# ESP32-P4-LP register map
Vendor: ESPRESSIF SYSTEMS (SHANGHAI) CO., LTD.; Series: ESP32 P-Series; File version: 3
32-bit RISC-V LP coprocessor on ESP32-P4 (ECO5+ silicon only)
CPU: RV32IMAC r0p0, little endian, no MPU, no FPU, 0 interrupt priority bits
Address unit: 32 bits
Registers are 32-bit, read-write, reset 0x0 unless marked. A register's access mark holds for its fields unless they carry their own. Offsets are from the block's base; lines under a group give offsets from that group; [hi:lo] are bit positions; {n}, {i} and the like mark numbered series; 'fields as' and 'values as' point back to an identical list; <NAME> marks a mode.

## Memory map
0x500A5800 LP2HP_PERI_PMS size 0xC0
0x50110000 LP_SYS size 0x124 — LP_SYS Peripheral
0x50111000 LP_AON_CLKRST size 0x54 — LP_AON_CLKRST Peripheral
0x50112000 LP_TIMER size 0x4C — Low-power Timer
0x50113000 LP_ANA_PERI size 0x144 — LP_ANA_PERI Peripheral
0x50114000 LP_HUK size 0x1A8 — LP_HUK Peripheral
0x50115000 PMU size 0x10E0
0x50116000 LP_WDT size 0x38 — Low-power Watchdog Timer
0x50118000 LP_MAILBOX size 0x320
0x50120000 LP_PERI size 0x2C — LP_PERI Peripheral
0x50121000 LP_UART size 0x84 — Low-power UART (Universal Asynchronous Receiver-Transmitter) Controller
0x50122000 LP_I2C0 size 0x440
0x50123000 LP_SPI size 0x560
0x50124000 LP_I2C_ANA_MST size 0x3C — LP_I2C_ANA_MST Peripheral
0x50125000 LP_I2S0 size 0x98 — Low-power I2S (Inter-IC Sound) Controller 0
0x50126000 LP_TRNG size 0x80
0x50127000 LP_ADC size 0x80 — Low-power Analog to Digital Converter
0x50128000 LP_TOUCH size 0x64 — LP_TOUCH Peripheral
0x5012A000 LP_GPIO size 0xEC — Low-power General Purpose Input/Output
0x5012B000 LP_IO_MUX size 0x54 — Low-power Input/Output Multiplexer
0x5012C000 LP_INTR size 0x18 — Low-power Interrupt Controller
0x5012E000 LP_PERI_PMS size 0x2A0
0x5012E800 HP2LP_PERI_PMS size 0xE0
0x5012F000 LP_TSENS size 0x38 — Low-power Temperature Sensor
0x60093000 PAU size 0x44 — PAU Peripheral

## Interrupts
3 LP_SW (LP_INTR) — LP software interrupt
7 LP_UART — LP UART interrupt
11 LP_SPI — LP SPI interrupt
15 LP_TRNG — LP TRNG interrupt
16 LP_I2C (LP_I2C0) — LP I2C interrupt
17 LP_IO (LP_GPIO) — LP GPIO/IO MUX interrupt
18 LP_ADC — LP ADC interrupt
19 LP_TOUCH — LP Touch sensor interrupt
20 LP_TSENS — LP temperature sensor interrupt
21 LP_EFUSE (LP_HUK) — LP eFuse / HUK interrupt
22 LP_SYSREG (LP_SYS) — LP system register interrupt
23 LP_ANA_PERI — LP analog peripheral interrupt
24 LP_PMU (PMU) — LP PMU interrupt
25 LP_MAILBOX — LP mailbox interrupt
26 LP_TIMER — LP timer interrupt
27 LP_WDT — LP watchdog interrupt
28 LP_RTC (LP_TIMER) — LP RTC interrupt

## LP2HP_PERI_PMS
Base 0x500A5800
0x00 TEE_LP2HP_PMS_DATE
  [31:0] TEE_TEE_DATE
0x04 TEE_PMS_CLK_EN
  [0] TEE_REG_CLK_EN
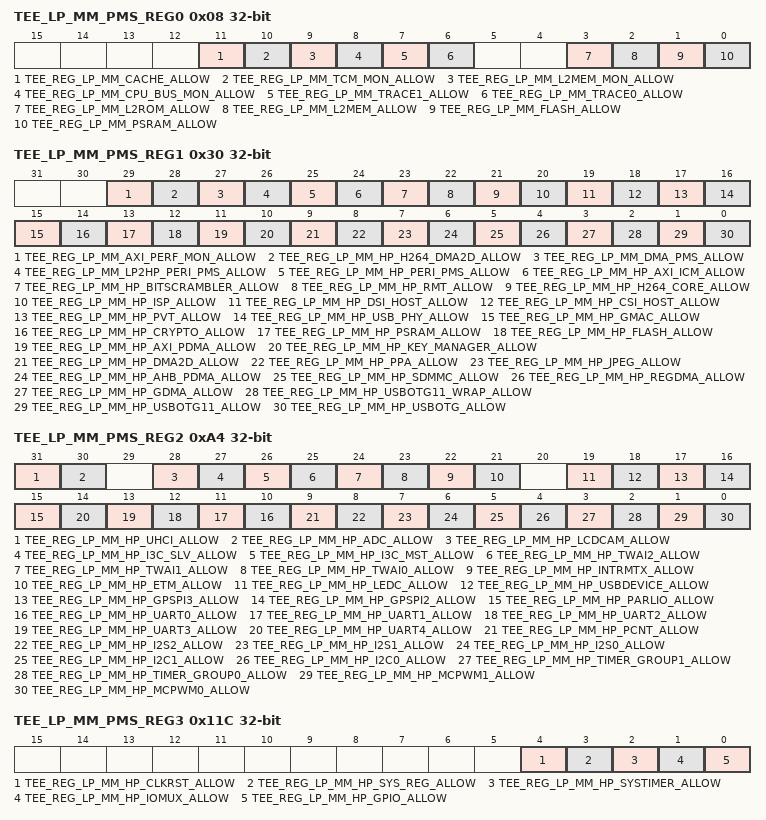
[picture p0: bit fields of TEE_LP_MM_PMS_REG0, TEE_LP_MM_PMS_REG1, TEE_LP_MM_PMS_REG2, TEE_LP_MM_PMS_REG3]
0x08 TEE_LP_MM_PMS_REG0
  [11] TEE_REG_LP_MM_CACHE_ALLOW, [10] TEE_REG_LP_MM_TCM_MON_ALLOW, [9] TEE_REG_LP_MM_L2MEM_MON_ALLOW, [8] TEE_REG_LP_MM_CPU_BUS_MON_ALLOW, [7] TEE_REG_LP_MM_TRACE1_ALLOW, [6] TEE_REG_LP_MM_TRACE0_ALLOW, [3] TEE_REG_LP_MM_L2ROM_ALLOW, [2] TEE_REG_LP_MM_L2MEM_ALLOW, [1] TEE_REG_LP_MM_FLASH_ALLOW, [0] TEE_REG_LP_MM_PSRAM_ALLOW
0x30 TEE_LP_MM_PMS_REG1
  [29] TEE_REG_LP_MM_AXI_PERF_MON_ALLOW, [28] TEE_REG_LP_MM_HP_H264_DMA2D_ALLOW, [27] TEE_REG_LP_MM_DMA_PMS_ALLOW, [26] TEE_REG_LP_MM_LP2HP_PERI_PMS_ALLOW, [25] TEE_REG_LP_MM_HP_PERI_PMS_ALLOW, [24] TEE_REG_LP_MM_HP_AXI_ICM_ALLOW, [23] TEE_REG_LP_MM_HP_BITSCRAMBLER_ALLOW, [22] TEE_REG_LP_MM_HP_RMT_ALLOW, [21] TEE_REG_LP_MM_HP_H264_CORE_ALLOW, [20] TEE_REG_LP_MM_HP_ISP_ALLOW, [19] TEE_REG_LP_MM_HP_DSI_HOST_ALLOW, [18] TEE_REG_LP_MM_HP_CSI_HOST_ALLOW, [17] TEE_REG_LP_MM_HP_PVT_ALLOW, [16] TEE_REG_LP_MM_HP_USB_PHY_ALLOW, [15] TEE_REG_LP_MM_HP_GMAC_ALLOW, [14] TEE_REG_LP_MM_HP_CRYPTO_ALLOW, [13] TEE_REG_LP_MM_HP_PSRAM_ALLOW, [12] TEE_REG_LP_MM_HP_FLASH_ALLOW, [11] TEE_REG_LP_MM_HP_AXI_PDMA_ALLOW, [10] TEE_REG_LP_MM_HP_KEY_MANAGER_ALLOW, [9] TEE_REG_LP_MM_HP_DMA2D_ALLOW, [8] TEE_REG_LP_MM_HP_PPA_ALLOW, [7] TEE_REG_LP_MM_HP_JPEG_ALLOW, [6] TEE_REG_LP_MM_HP_AHB_PDMA_ALLOW, [5] TEE_REG_LP_MM_HP_SDMMC_ALLOW, [4] TEE_REG_LP_MM_HP_REGDMA_ALLOW, [3] TEE_REG_LP_MM_HP_GDMA_ALLOW, [2] TEE_REG_LP_MM_HP_USBOTG11_WRAP_ALLOW, [1] TEE_REG_LP_MM_HP_USBOTG11_ALLOW, [0] TEE_REG_LP_MM_HP_USBOTG_ALLOW
0xA4 TEE_LP_MM_PMS_REG2
  [31] TEE_REG_LP_MM_HP_UHCI_ALLOW, [30] TEE_REG_LP_MM_HP_ADC_ALLOW, [28] TEE_REG_LP_MM_HP_LCDCAM_ALLOW, [27] TEE_REG_LP_MM_HP_I3C_SLV_ALLOW, [26] TEE_REG_LP_MM_HP_I3C_MST_ALLOW, [25] TEE_REG_LP_MM_HP_TWAI2_ALLOW, [24] TEE_REG_LP_MM_HP_TWAI1_ALLOW, [23] TEE_REG_LP_MM_HP_TWAI0_ALLOW, [22] TEE_REG_LP_MM_HP_INTRMTX_ALLOW, [21] TEE_REG_LP_MM_HP_ETM_ALLOW, [19] TEE_REG_LP_MM_HP_LEDC_ALLOW, [18] TEE_REG_LP_MM_HP_USBDEVICE_ALLOW, [17] TEE_REG_LP_MM_HP_GPSPI3_ALLOW, [16] TEE_REG_LP_MM_HP_GPSPI2_ALLOW, [15] TEE_REG_LP_MM_HP_PARLIO_ALLOW, [n+10] TEE_REG_LP_MM_HP_UART{n}_ALLOW (n=0..4), [9] TEE_REG_LP_MM_HP_PCNT_ALLOW, [8] TEE_REG_LP_MM_HP_I2S2_ALLOW, [7] TEE_REG_LP_MM_HP_I2S1_ALLOW, [6] TEE_REG_LP_MM_HP_I2S0_ALLOW, [5] TEE_REG_LP_MM_HP_I2C1_ALLOW, [4] TEE_REG_LP_MM_HP_I2C0_ALLOW, [3] TEE_REG_LP_MM_HP_TIMER_GROUP1_ALLOW, [2] TEE_REG_LP_MM_HP_TIMER_GROUP0_ALLOW, [1] TEE_REG_LP_MM_HP_MCPWM1_ALLOW, [0] TEE_REG_LP_MM_HP_MCPWM0_ALLOW
0x11C TEE_LP_MM_PMS_REG3
  [4] TEE_REG_LP_MM_HP_CLKRST_ALLOW, [3] TEE_REG_LP_MM_HP_SYS_REG_ALLOW, [2] TEE_REG_LP_MM_HP_SYSTIMER_ALLOW, [1] TEE_REG_LP_MM_HP_IOMUX_ALLOW, [0] TEE_REG_LP_MM_HP_GPIO_ALLOW

## Licence text in the file
Copyright 2026 Espressif Systems (Shanghai) PTE LTD Licensed under the Apache License, Version 2.0 (the "License"); you may not use this file except in compliance with the License. You may obtain a copy of the License at http://www.apache.org/licenses/LICENSE-2.0 Unless required by applicable law or agreed to in writing, software distributed under the License is distributed on an "AS IS" BASIS, WITHOUT WARRANTIES OR CONDITIONS OF ANY KIND, either express or implied. See the License for the specific language governing permissions and limitations under the License.
